AUTOSAR XML (schema 00046)
package /Component_Composition_1_package
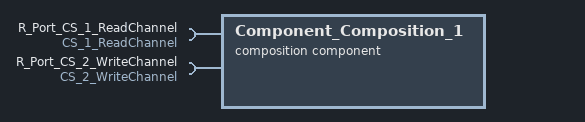
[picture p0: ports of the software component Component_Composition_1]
  composition sw component type Component_Composition_1
    require port R_Port_CS_1_ReadChannel: required-interface=CS_1_ReadChannel
    require port R_Port_CS_2_WriteChannel: required-interface=CS_2_WriteChannel
    component Component_Composition_1_Prototype_1: type=Application1_SWC_ButtonStateReading
    component Component_Composition_1_Prototype_2: type=Application2_SWC_LedSwitching
